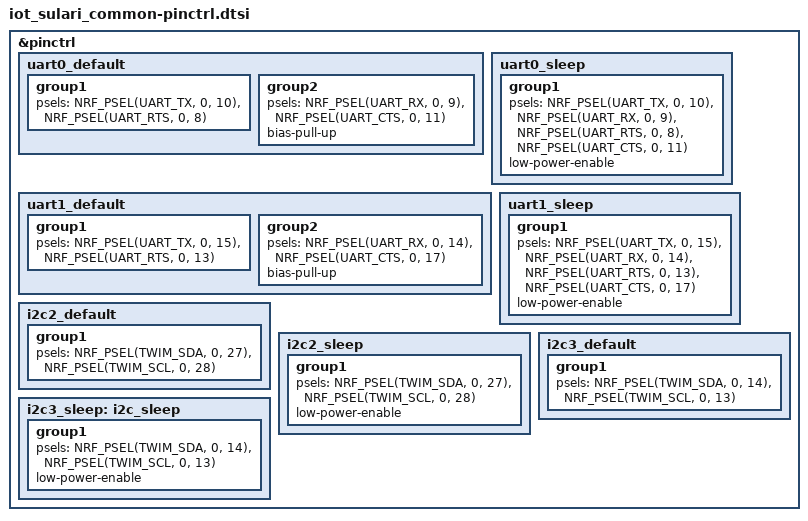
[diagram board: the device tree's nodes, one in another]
/*
 * Copyright (c) 2022 Nordic Semiconductor
 * SPDX-License-Identifier: Apache-2.0
 */

&pinctrl {
	uart0_default: uart0_default {
		group1 {
			psels = <NRF_PSEL(UART_TX, 0, 10)>,
				<NRF_PSEL(UART_RTS, 0, 8)>;
		};
		group2 {
			psels = <NRF_PSEL(UART_RX, 0, 9)>,
				<NRF_PSEL(UART_CTS, 0, 11)>;
			bias-pull-up;
		};
	};

	uart0_sleep: uart0_sleep {
		group1 {
			psels = <NRF_PSEL(UART_TX, 0, 10)>,
				<NRF_PSEL(UART_RX, 0, 9)>,
				<NRF_PSEL(UART_RTS, 0, 8)>,
				<NRF_PSEL(UART_CTS, 0, 11)>;
			low-power-enable;
		};
	};

	uart1_default: uart1_default {
		group1 {
			psels = <NRF_PSEL(UART_TX, 0, 15)>,
				<NRF_PSEL(UART_RTS, 0, 13)>;
		};
		group2 {
			psels = <NRF_PSEL(UART_RX, 0, 14)>,
				<NRF_PSEL(UART_CTS, 0, 17)>;
			bias-pull-up;
		};
	};

	uart1_sleep: uart1_sleep {
		group1 {
			psels = <NRF_PSEL(UART_TX, 0, 15)>,
				<NRF_PSEL(UART_RX, 0, 14)>,
				<NRF_PSEL(UART_RTS, 0, 13)>,
				<NRF_PSEL(UART_CTS, 0, 17)>;
			low-power-enable;
		};
	};

	i2c2_default: i2c2_default {
		group1 {
			psels = <NRF_PSEL(TWIM_SDA, 0, 27)>,
				<NRF_PSEL(TWIM_SCL, 0, 28)>;
		};
	};

	i2c2_sleep: i2c2_sleep {
		group1 {
			psels = <NRF_PSEL(TWIM_SDA, 0, 27)>,
				<NRF_PSEL(TWIM_SCL, 0, 28)>;
			low-power-enable;
		};
	};

	i2c3_default: i2c3_default {
        group1 {
            psels = <NRF_PSEL(TWIM_SDA, 0, 14)>,
                    <NRF_PSEL(TWIM_SCL, 0, 13)>;
        };
    };

    i2c3_sleep: i2c_sleep {
        group1 {
            psels = <NRF_PSEL(TWIM_SDA, 0, 14)>,
                    <NRF_PSEL(TWIM_SCL, 0, 13)>;
            low-power-enable;
      };
    };
};
